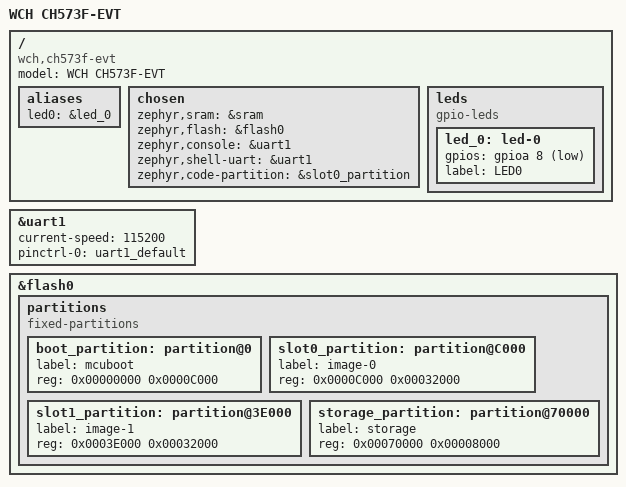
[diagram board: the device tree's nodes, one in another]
/*
 * Copyright (c) 2023-2024 Chen Xingyu <hi@xingrz.me>
 * SPDX-License-Identifier: Apache-2.0
 */

/dts-v1/;

#include <zephyr/dt-bindings/gpio/gpio.h>
#include <wch/ch57x/ch573f.dtsi>
#include <wch/ch57x/ch573f-pinctrl.dtsi>

/ {
	model = "WCH CH573F-EVT";
	compatible = "wch,ch573f-evt";

	aliases {
		led0 = &led_0;
	};

	chosen {
		zephyr,sram = &sram;
		zephyr,flash = &flash0;
		zephyr,console = &uart1;
		zephyr,shell-uart = &uart1;
		zephyr,code-partition = &slot0_partition;
	};

	leds {
		compatible = "gpio-leds";

		led_0: led-0 {
			gpios = <&gpioa 8 GPIO_ACTIVE_LOW>;
			label = "LED0";
		};
	};
};

&uart1 {
	status = "okay";
	current-speed = <115200>;
	pinctrl-0 = <&uart1_default>;
	pinctrl-names = "default";
};

&flash0 {

	partitions {
		compatible = "fixed-partitions";
		#address-cells = <1>;
		#size-cells = <1>;

		/*
		 * WCH Code Flash area
		 */
		boot_partition: partition@0 {
			label = "mcuboot";
			reg = <0x00000000 0x0000C000>;
		};
		slot0_partition: partition@C000 {
			label = "image-0";
			reg = <0x0000C000 0x00032000>;
		};
		slot1_partition: partition@3E000 {
			label = "image-1";
			reg = <0x0003E000 0x00032000>;
		};

		/*
		 * WCH Data Flash area
		 * The flash starting at 0x00070000 and ending at
		 * 0x00077fff is reserved for use by the application.
		 */

		/*
		 * Storage partition will be used by FCB/LittleFS/NVS
		 * if enabled.
		 */
		storage_partition: partition@70000 {
			label = "storage";
			reg = <0x00070000 0x00008000>;
		};
	};
};
